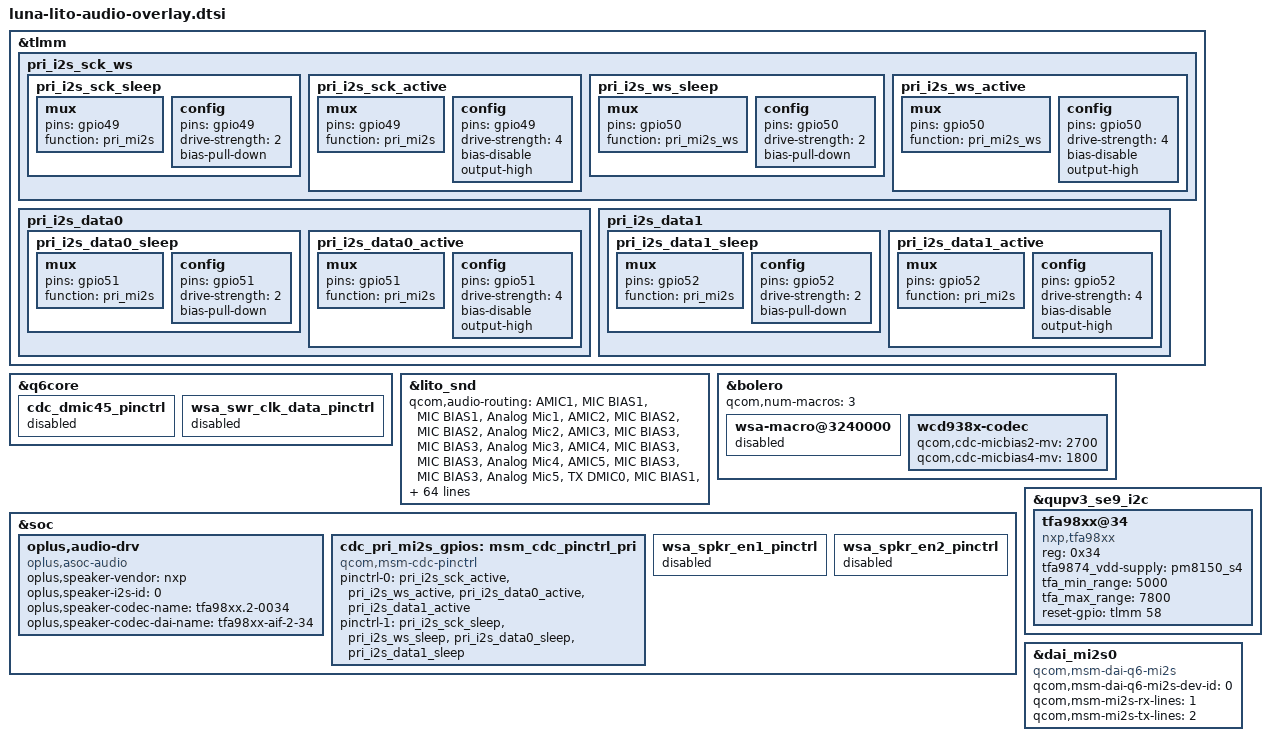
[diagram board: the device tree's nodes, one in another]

&tlmm {
        pri_i2s_sck_ws {
                pri_i2s_sck_sleep: pri_i2s_sck_sleep {
                        mux {
                                pins = "gpio49";
                                function = "pri_mi2s";
                        };

                        config {
                                pins = "gpio49";
                                drive-strength = <2>;   /* 2 mA */
                                bias-pull-down;
                        };
                };

                pri_i2s_sck_active: pri_i2s_sck_active {
                        mux {
                                pins = "gpio49";
                                function = "pri_mi2s";
                        };

                        config {
                                pins = "gpio49";
                                drive-strength = <4>;   /* 4 mA */
                                bias-disable;
                                output-high;
                        };
                };

                pri_i2s_ws_sleep: pri_i2s_ws_sleep {
                        mux {
                                pins = "gpio50";
                                function = "pri_mi2s_ws";
                        };

                        config {
                                pins = "gpio50";
                                drive-strength = <2>;   /* 2 mA */
                                bias-pull-down;
                        };
                };

                pri_i2s_ws_active: pri_i2s_ws_active {
                        mux {
                                pins = "gpio50";
                                function = "pri_mi2s_ws";
                        };

                        config {
                                pins = "gpio50";
                                drive-strength = <4>;   /* 4 mA */
                                bias-disable;
                                output-high;
                        };
                };
        };

        pri_i2s_data0 {
                pri_i2s_data0_sleep: pri_i2s_data0_sleep {
                        mux {
                                pins = "gpio51";
                                function = "pri_mi2s";
                        };

                        config {
                                pins = "gpio51";
                                drive-strength = <2>;   /* 2 mA */
                                bias-pull-down;
                        };
                };

                pri_i2s_data0_active: pri_i2s_data0_active {
                        mux {
                                pins = "gpio51";
                                function = "pri_mi2s";
                        };

                        config {
                                pins = "gpio51";
                                drive-strength = <4>;   /* 4 mA */
                                bias-disable;
                                output-high;
                        };
                };
        };

        pri_i2s_data1 {
                pri_i2s_data1_sleep: pri_i2s_data1_sleep {
                        mux {
                                pins = "gpio52";
                                function = "pri_mi2s";
                        };

                        config {
                                pins = "gpio52";
                                drive-strength = <2>;   /* 2 mA */
                                bias-pull-down;
                        };
                };

                pri_i2s_data1_active: pri_i2s_data1_active {
                        mux {
                                pins = "gpio52";
                                function = "pri_mi2s";
                        };

                        config {
                                pins = "gpio52";
                                drive-strength = <4>;   /* 4 mA */
                                bias-disable;
                                output-high;
                        };
                };
        };
};

&q6core {
        cdc_dmic45_pinctrl {
                //use lpi_gpio12/13 conflict with tfa98xx i2s pin
                status = "disabled";
        };

        wsa_swr_clk_data_pinctrl {
                status = "disabled";
        };
};

&lito_snd {
        qcom,audio-routing =
                "AMIC1", "MIC BIAS1",
                "MIC BIAS1", "Analog Mic1",
                "AMIC2", "MIC BIAS2",
                "MIC BIAS2", "Analog Mic2",
                "AMIC3", "MIC BIAS3",
                "MIC BIAS3", "Analog Mic3",
                "AMIC4", "MIC BIAS3",
                "MIC BIAS3", "Analog Mic4",
                "AMIC5", "MIC BIAS3",
                "MIC BIAS3", "Analog Mic5",
                "TX DMIC0", "MIC BIAS1",
                "MIC BIAS1", "Digital Mic0",
                "TX DMIC1", "MIC BIAS1",
                "MIC BIAS1", "Digital Mic1",
                "TX DMIC2", "MIC BIAS3",
                "MIC BIAS3", "Digital Mic2",
                "TX DMIC3", "MIC BIAS3",
                "MIC BIAS3", "Digital Mic3",
                "TX DMIC4", "MIC BIAS4",
                "MIC BIAS4", "Digital Mic4",
                "TX DMIC5", "MIC BIAS4",
                "MIC BIAS4", "Digital Mic5",
                //anc mic, bias4
                "DMIC3", "MIC BIAS4",
                "MIC BIAS4", "Digital Mic2",
                "DMIC4", "MIC BIAS4",
                "MIC BIAS4", "Digital Mic3",
                //main mic, bias1
                "DMIC5", "MIC BIAS1",
                "MIC BIAS1", "Digital Mic4",
                "DMIC6", "MIC BIAS1",
                "MIC BIAS1", "Digital Mic5",
                //sec mic, bias3
                "DMIC7", "MIC BIAS3",
                "MIC BIAS3", "Digital Mic6",
                "DMIC8", "MIC BIAS3",
                "MIC BIAS3", "Digital Mic7",
                "IN1_HPHL", "HPHL_OUT",
                "IN2_HPHR", "HPHR_OUT",
                "IN3_AUX", "AUX_OUT",
                "TX SWR_ADC0", "ADC1_OUTPUT",
                "TX SWR_ADC1", "ADC2_OUTPUT",
                "TX SWR_ADC2", "ADC3_OUTPUT",
                "TX SWR_ADC3", "ADC4_OUTPUT",
                "TX SWR_DMIC0", "DMIC1_OUTPUT",
                "TX SWR_DMIC1", "DMIC2_OUTPUT",
                "TX SWR_DMIC2", "DMIC3_OUTPUT",
                "TX SWR_DMIC3", "DMIC4_OUTPUT",
                "TX SWR_DMIC4", "DMIC5_OUTPUT",
                "TX SWR_DMIC5", "DMIC6_OUTPUT",
                "TX SWR_DMIC6", "DMIC7_OUTPUT",
                "TX SWR_DMIC7", "DMIC8_OUTPUT",
                "WSA SRC0_INP", "SRC0",
                "WSA_TX DEC0_INP", "TX DEC0 MUX",
                "WSA_TX DEC1_INP", "TX DEC1 MUX",
                "RX_TX DEC0_INP", "TX DEC0 MUX",
                "RX_TX DEC1_INP", "TX DEC1 MUX",
                "RX_TX DEC2_INP", "TX DEC2 MUX",
                "RX_TX DEC3_INP", "TX DEC3 MUX",
                "SpkrLeft IN", "WSA_SPK1 OUT",
                "SpkrRight IN", "WSA_SPK2 OUT",
                "VA_AIF1 CAP", "VA_SWR_CLK",
                "VA_AIF2 CAP", "VA_SWR_CLK",
                "VA_AIF3 CAP", "VA_SWR_CLK",
                "VA MIC BIAS3", "Digital Mic0",
                "VA MIC BIAS3", "Digital Mic1",
                "VA MIC BIAS1", "Digital Mic2",
                "VA MIC BIAS1", "Digital Mic3",
                "VA MIC BIAS4", "Digital Mic4",
                "VA MIC BIAS4", "Digital Mic5",
                "VA DMIC0", "VA MIC BIAS3",
                "VA DMIC1", "VA MIC BIAS3",
                "VA DMIC2", "VA MIC BIAS1",
                "VA DMIC3", "VA MIC BIAS1",
                "VA DMIC4", "VA MIC BIAS4",
                "VA DMIC5", "VA MIC BIAS4",
                "VA SWR_ADC0", "VA_SWR_CLK",
                "VA SWR_ADC1", "VA_SWR_CLK",
                "VA SWR_ADC2", "VA_SWR_CLK",
                "VA SWR_ADC3", "VA_SWR_CLK",
                "VA SWR_MIC0", "VA_SWR_CLK",
                "VA SWR_MIC1", "VA_SWR_CLK",
                "VA SWR_MIC2", "VA_SWR_CLK",
                "VA SWR_MIC3", "VA_SWR_CLK",
                "VA SWR_MIC4", "VA_SWR_CLK",
                "VA SWR_MIC5", "VA_SWR_CLK",
                "VA SWR_MIC6", "VA_SWR_CLK",
                "VA SWR_MIC7", "VA_SWR_CLK",
                "VA SWR_ADC0", "ADC1_OUTPUT",
                "VA SWR_ADC1", "ADC2_OUTPUT",
                "VA SWR_ADC2", "ADC3_OUTPUT",
                "VA SWR_ADC3", "ADC4_OUTPUT",
                "VA SWR_MIC0", "DMIC1_OUTPUT",
                "VA SWR_MIC1", "DMIC2_OUTPUT",
                "VA SWR_MIC2", "DMIC3_OUTPUT",
                "VA SWR_MIC3", "DMIC4_OUTPUT",
                "VA SWR_MIC4", "DMIC5_OUTPUT",
                "VA SWR_MIC5", "DMIC6_OUTPUT",
                "VA SWR_MIC6", "DMIC7_OUTPUT",
                "VA SWR_MIC7", "DMIC8_OUTPUT";

        qcom,pri-mi2s-gpios = <&cdc_pri_mi2s_gpios>;

        qcom,wsa-max-devs = <0>;

        qcom,msm-mbhc-hs-mic-max-threshold-mv = <2600>;
        qcom,msm-mbhc-hs-mic-min-threshold-mv = <75>;

        oplus,mbhc-check-cross-conn = <0>;

        oplus,mbhc-headset-bias-alwayon = <0>;

        qcom,mi2s-audio-intf = <1>;
        qcom,auxpcm-audio-intf = <1>;
        qcom,tdm-audio-intf = <1>;
};

&bolero {
        qcom,num-macros = <3>;

        wsa-macro@3240000 {
                status = "disabled";
        };

        wcd938x-codec {
                qcom,cdc-micbias2-mv = <2700>;
                qcom,cdc-micbias4-mv = <1800>;
        };
};

&soc {
        oplus,audio-drv {
                compatible = "oplus,asoc-audio";
                //for nxp speaker
                oplus,speaker-vendor = "nxp";
                oplus,speaker-i2s-id = <0>;
                oplus,speaker-codec-name = "tfa98xx.2-0034";
                oplus,speaker-codec-dai-name = "tfa98xx-aif-2-34";
        };

        cdc_pri_mi2s_gpios: msm_cdc_pinctrl_pri {
                compatible = "qcom,msm-cdc-pinctrl";
                pinctrl-names = "aud_active", "aud_sleep";
                pinctrl-0 = <&pri_i2s_sck_active &pri_i2s_ws_active
                             &pri_i2s_data0_active &pri_i2s_data1_active>;
                pinctrl-1 = <&pri_i2s_sck_sleep &pri_i2s_ws_sleep
                             &pri_i2s_data0_sleep &pri_i2s_data1_sleep>;
        };

        wsa_spkr_en1_pinctrl {
                status = "disabled";
        };

        wsa_spkr_en2_pinctrl {
                status = "disabled";
        };
};

&qupv3_se9_i2c {
        status = "okay";
        tfa98xx@34 {
                compatible = "nxp,tfa98xx";
                reg = <0x34>;
                tfa9874_vdd-supply = <&pm8150_s4>;
                tfa_min_range = <5000>;
                tfa_max_range = <7800>;
                reset-gpio = <&tlmm 58 0x00>;
                status = "okay";
        };
};

//Add for tfa98xx
&dai_mi2s0 {
        compatible = "qcom,msm-dai-q6-mi2s";
        qcom,msm-dai-q6-mi2s-dev-id = <0>;
        qcom,msm-mi2s-rx-lines = <1>;
        qcom,msm-mi2s-tx-lines = <2>;
};
